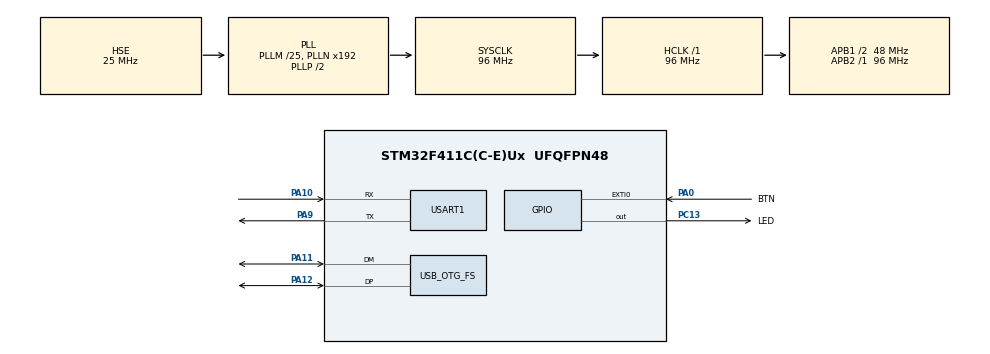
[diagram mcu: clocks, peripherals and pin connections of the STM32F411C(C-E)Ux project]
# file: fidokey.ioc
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Mcu.Family=STM32F4
RCC.CortexFreq_Value=96000000
PA10.Mode=Asynchronous
PC13-ANTI_TAMP.GPIO_Label=LED
PH1\ -\ OSC_OUT.Mode=HSE-External-Oscillator
PA11.Mode=Device_Only
RCC.APB1CLKDivider=RCC_HCLK_DIV2
PA0-WKUP.GPIO_ModeDefaultEXTI=GPIO_MODE_IT_RISING_FALLING
PC13-ANTI_TAMP.PinState=GPIO_PIN_SET
RCC.SYSCLKSource=RCC_SYSCLKSOURCE_PLLCLK
ProjectManager.StackSize=0x400
PA0-WKUP.GPIO_Label=BTN
PA0-WKUP.Signal=GPXTI0
PA13.Signal=SYS_JTMS-SWDIO
PA9.Mode=Asynchronous
PA12.Signal=USB_OTG_FS_DP
PH0\ -\ OSC_IN.Mode=HSE-External-Oscillator
PH0\ -\ OSC_IN.Signal=RCC_OSC_IN
ProjectManager.TargetToolchain=STM32CubeIDE
RCC.HCLKFreq_Value=96000000
RCC.APB2TimFreq_Value=96000000
PA9.Signal=USART1_TX
RCC.LSE_VALUE=32768
RCC.AHBFreq_Value=96000000
RCC.HSE_VALUE=25000000
PH1\ -\ OSC_OUT.Signal=RCC_OSC_OUT
board=custom
PC13-ANTI_TAMP.Signal=GPIO_Output
RCC.VCOOutputFreq_Value=192000000
PC13-ANTI_TAMP.GPIO_ModeDefaultOutputPP=GPIO_MODE_OUTPUT_OD
RCC.APB2Freq_Value=96000000
PA14.Mode=Serial_Wire
PA13.Mode=Serial_Wire
Mcu.Name=STM32F411C(C-E)Ux
RCC.48MHZClocksFreq_Value=48000000
NVIC.EXTI0_IRQn=true\:0\:0\:false\:false\:true\:true\:true
RCC.SYSCLKFreq_VALUE=96000000
Mcu.Package=UFQFPN48
PA12.Mode=Device_Only
USART1.VirtualMode=VM_ASYNC
PA11.Signal=USB_OTG_FS_DM
PA10.Signal=USART1_RX
PA14.Signal=SYS_JTCK-SWCLK
USB_OTG_FS.VirtualMode=Device_Only
ProjectManager.HeapSize=0x200
RCC.HSI_VALUE=16000000
NVIC.PriorityGroup=NVIC_PRIORITYGROUP_4
RCC.PLLM=25
RCC.APB1TimFreq_Value=96000000
PA0-WKUP.GPIO_PuPd=GPIO_PULLUP
RCC.APB1Freq_Value=48000000

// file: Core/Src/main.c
/* USER CODE BEGIN Header */
/**
  ******************************************************************************
  * @file           : main.c
  * @brief          : Main program body
  ******************************************************************************
  * @attention
  *
  * <h2><center>&copy; Copyright (c) 2021 STMicroelectronics.
  * All rights reserved.</center></h2>
  *
  * This software component is licensed by ST under BSD 3-Clause license,
  * the "License"; You may not use this file except in compliance with the
  * License. You may obtain a copy of the License at:
  *                        opensource.org/licenses/BSD-3-Clause
  *
  ******************************************************************************
  */
/* USER CODE END Header */
#include "main.h"

UART_HandleTypeDef huart1;

PCD_HandleTypeDef hpcd_USB_OTG_FS;

void SystemClock_Config(void);
static void MX_GPIO_Init(void);
static void MX_USB_OTG_FS_PCD_Init(void);
static void MX_USART1_UART_Init(void);

int main(void)
{

  /* MCU Configuration--------------------------------------------------------*/

  /* Reset of all peripherals, Initializes the Flash interface and the Systick. */
  HAL_Init();

  /* Configure the system clock */
  SystemClock_Config();

  /* Initialize all configured peripherals */
  MX_GPIO_Init();
  MX_USB_OTG_FS_PCD_Init();
  MX_USART1_UART_Init();

  /* Infinite loop */
  /* USER CODE BEGIN WHILE */

  uint32_t then = 0, now = 0;

  while (1)
  {

	  now = HAL_GetTick();
	  if (now - then > 500) { // More than 500 ms has passed

		  HAL_GPIO_TogglePin(LED_GPIO_Port, LED_Pin);

		  then = now;
	  }

    /* USER CODE END WHILE */

  }
}

void SystemClock_Config(void)
{
  RCC_OscInitTypeDef RCC_OscInitStruct = {0};
  RCC_ClkInitTypeDef RCC_ClkInitStruct = {0};

  /** Configure the main internal regulator output voltage
  */
  __HAL_RCC_PWR_CLK_ENABLE();
  __HAL_PWR_VOLTAGESCALING_CONFIG(PWR_REGULATOR_VOLTAGE_SCALE1);
  /** Initializes the RCC Oscillators according to the specified parameters
  * in the RCC_OscInitTypeDef structure.
  */
  RCC_OscInitStruct.OscillatorType = RCC_OSCILLATORTYPE_HSE;
  RCC_OscInitStruct.HSEState = RCC_HSE_ON;
  RCC_OscInitStruct.PLL.PLLState = RCC_PLL_ON;
  RCC_OscInitStruct.PLL.PLLSource = RCC_PLLSOURCE_HSE;
  RCC_OscInitStruct.PLL.PLLM = 25;
  RCC_OscInitStruct.PLL.PLLN = 192;
  RCC_OscInitStruct.PLL.PLLP = RCC_PLLP_DIV2;
  RCC_OscInitStruct.PLL.PLLQ = 4;
  if (HAL_RCC_OscConfig(&RCC_OscInitStruct) != HAL_OK)
  {
    Error_Handler();
  }
  /** Initializes the CPU, AHB and APB buses clocks
  */
  RCC_ClkInitStruct.ClockType = RCC_CLOCKTYPE_HCLK|RCC_CLOCKTYPE_SYSCLK
                              |RCC_CLOCKTYPE_PCLK1|RCC_CLOCKTYPE_PCLK2;
  RCC_ClkInitStruct.SYSCLKSource = RCC_SYSCLKSOURCE_PLLCLK;
  RCC_ClkInitStruct.AHBCLKDivider = RCC_SYSCLK_DIV1;
  RCC_ClkInitStruct.APB1CLKDivider = RCC_HCLK_DIV2;
  RCC_ClkInitStruct.APB2CLKDivider = RCC_HCLK_DIV1;

  if (HAL_RCC_ClockConfig(&RCC_ClkInitStruct, FLASH_LATENCY_3) != HAL_OK)
  {
    Error_Handler();
  }
}

static void MX_USART1_UART_Init(void)
{

  huart1.Instance = USART1;
  huart1.Init.BaudRate = 115200;
  huart1.Init.WordLength = UART_WORDLENGTH_8B;
  huart1.Init.StopBits = UART_STOPBITS_1;
  huart1.Init.Parity = UART_PARITY_NONE;
  huart1.Init.Mode = UART_MODE_TX_RX;
  huart1.Init.HwFlowCtl = UART_HWCONTROL_NONE;
  huart1.Init.OverSampling = UART_OVERSAMPLING_16;
  if (HAL_UART_Init(&huart1) != HAL_OK)
  {
    Error_Handler();
  }

}

static void MX_USB_OTG_FS_PCD_Init(void)
{

  hpcd_USB_OTG_FS.Instance = USB_OTG_FS;
  hpcd_USB_OTG_FS.Init.dev_endpoints = 4;
  hpcd_USB_OTG_FS.Init.speed = PCD_SPEED_FULL;
  hpcd_USB_OTG_FS.Init.dma_enable = DISABLE;
  hpcd_USB_OTG_FS.Init.phy_itface = PCD_PHY_EMBEDDED;
  hpcd_USB_OTG_FS.Init.Sof_enable = DISABLE;
  hpcd_USB_OTG_FS.Init.low_power_enable = DISABLE;
  hpcd_USB_OTG_FS.Init.lpm_enable = DISABLE;
  hpcd_USB_OTG_FS.Init.vbus_sensing_enable = DISABLE;
  hpcd_USB_OTG_FS.Init.use_dedicated_ep1 = DISABLE;
  if (HAL_PCD_Init(&hpcd_USB_OTG_FS) != HAL_OK)
  {
    Error_Handler();
  }

}

static void MX_GPIO_Init(void)
{
  GPIO_InitTypeDef GPIO_InitStruct = {0};

  /* GPIO Ports Clock Enable */
  __HAL_RCC_GPIOC_CLK_ENABLE();
  __HAL_RCC_GPIOH_CLK_ENABLE();
  __HAL_RCC_GPIOA_CLK_ENABLE();

  /*Configure GPIO pin Output Level */
  HAL_GPIO_WritePin(LED_GPIO_Port, LED_Pin, GPIO_PIN_SET);

  /*Configure GPIO pin : LED_Pin */
  GPIO_InitStruct.Pin = LED_Pin;
  GPIO_InitStruct.Mode = GPIO_MODE_OUTPUT_OD;
  GPIO_InitStruct.Pull = GPIO_NOPULL;
  GPIO_InitStruct.Speed = GPIO_SPEED_FREQ_LOW;
  HAL_GPIO_Init(LED_GPIO_Port, &GPIO_InitStruct);

  /*Configure GPIO pin : BTN_Pin */
  GPIO_InitStruct.Pin = BTN_Pin;
  GPIO_InitStruct.Mode = GPIO_MODE_IT_RISING_FALLING;
  GPIO_InitStruct.Pull = GPIO_PULLUP;
  HAL_GPIO_Init(BTN_GPIO_Port, &GPIO_InitStruct);

  /* EXTI interrupt init*/
  HAL_NVIC_SetPriority(EXTI0_IRQn, 0, 0);
  HAL_NVIC_EnableIRQ(EXTI0_IRQn);

}

void Error_Handler(void)
{
  __disable_irq();
  while (1)
  {
  }
}

/************************ (C) COPYRIGHT STMicroelectronics *****END OF FILE****/
